# GD32C231 register map
File version: 1.0
CPU: CM23 r0p0, little endian, MPU, FPU, 4 interrupt priority bits
Registers are 32-bit, read-write, reset 0x0 unless marked. A register's access mark holds for its fields unless they carry their own. Offsets are from the block's base; [hi:lo] are bit positions.

## WWDGT — Window watchdog timer
Base 0x40002C00
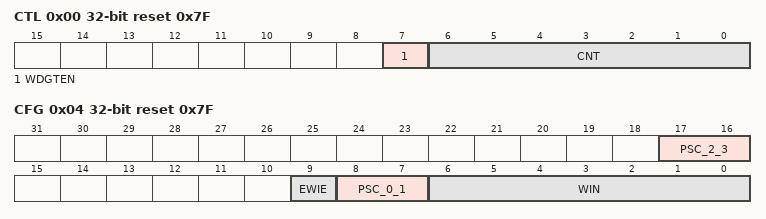
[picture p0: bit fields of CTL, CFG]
0x00 CTL reset 0x7F — Control register
  [7] WDGTEN — Activation bit
  [6:0] CNT — 7-bit counter
0x04 CFG reset 0x7F — Configuration register
  [17:16] PSC_2_3 — Prescaler
  [9] EWIE — Early wakeup interrupt
  [8:7] PSC_0_1 — Prescaler
  [6:0] WIN — 7-bit window value
0x08 STAT — Status register
  [0] EWIF — Early wakeup interrupt flag

## CMP — Comparator
Base 0x40017C00
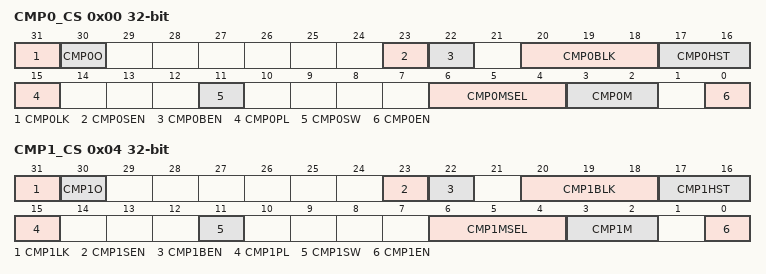
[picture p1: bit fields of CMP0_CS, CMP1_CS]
0x00 CMP0_CS access per field — CMP0 Control / Status register
  [31] CMP0LK rw — CMP0 lock
  [30] CMP0O ro — CMP0 output state
  [23] CMP0SEN rw — Voltage scaler enable bit
  [22] CMP0BEN rw — Scaler bridge enable bit
  [20:18] CMP0BLK rw — CMP0 output blanking source
  [17:16] CMP0HST rw — CMP0 hysteresis
  [15] CMP0PL rw — Polarity of CMP0 output
  [11] CMP0SW rw — CMP0 switch
  [6:4] CMP0MSEL rw — CMP0_IM input selection
  [3:2] CMP0M rw — CMP0 mode
  [0] CMP0EN rw — CMP0 enable
0x04 CMP1_CS access per field — CMP1 Control / Status register
  [31] CMP1LK rw — CMP1 lock
  [30] CMP1O ro — CMP1 output state
  [23] CMP1SEN rw — Voltage scaler enable bit
  [22] CMP1BEN rw — Scaler bridge enable bit
  [20:18] CMP1BLK rw — CMP1 output blanking source
  [17:16] CMP1HST rw — CMP1 hysteresis
  [15] CMP1PL rw — Polarity of CMP1 output
  [11] CMP1SW rw — CMP1 switch
  [6:4] CMP1MSEL rw — CMP1_IM input selection
  [3:2] CMP1M rw — CMP1 mode
  [0] CMP1EN rw — CMP1 enable.

## SPI1 — Serial peripheral interface
Base 0x40003800
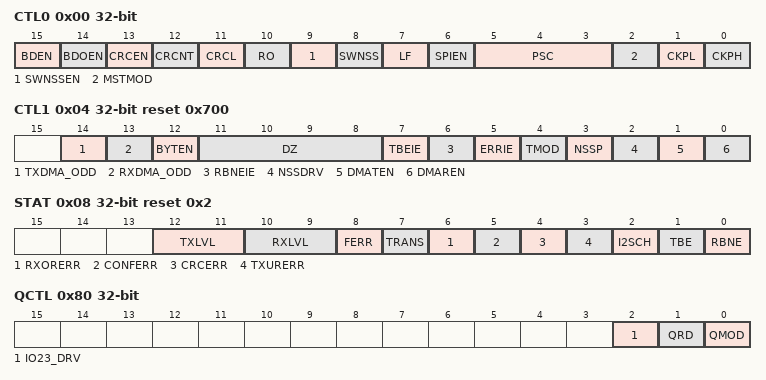
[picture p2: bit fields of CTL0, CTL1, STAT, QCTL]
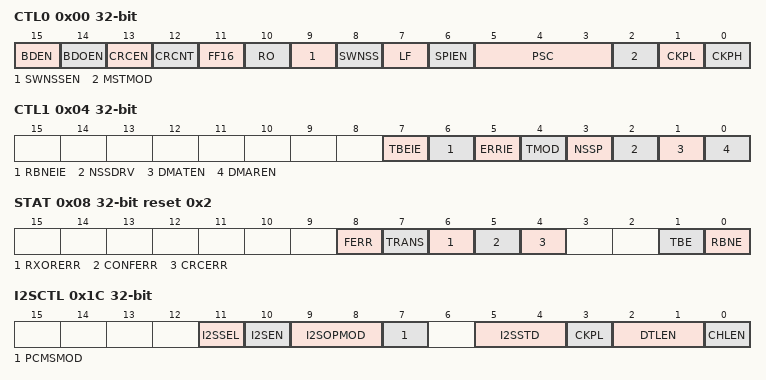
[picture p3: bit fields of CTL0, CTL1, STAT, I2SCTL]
0x00 CTL0 — control register 0
  [15] BDEN — Bidirectional enable
  [14] BDOEN — Bidirectional Transmit output enable
  [13] CRCEN — Hardware CRC calculation enable
  [12] CRCNT — CRC transfer next
  [11] CRCL — CRC length
  [10] RO — Receive only
  [9] SWNSSEN — NSS Software Mode Selection
  [8] SWNSS — NSS Pin Selection In NSS Software Mode
  [7] LF — LSB First Mode
  [6] SPIEN — SPI enable
  [5:3] PSC — Master Clock Prescaler Selection
  [2] MSTMOD — Master Mode Enable
  [1] CKPL — Clock Polarity Selection
  [0] CKPH — Clock Phase Selection
0x04 CTL1 reset 0x700 — control register 1
  [14] TXDMA_ODD — Odd bytes in TX DMA channel
  [13] RXDMA_ODD — Odd bytes in RX DMA channel
  [12] BYTEN — Byte access enable
  [11:8] DZ — Date size
  [7] TBEIE — Transmit Buffer Empty Interrupt Enable
  [6] RBNEIE — Receive Buffer Not Empty Interrupt Enable
  [5] ERRIE — Error interrupt enable
  [4] TMOD — SPI TI Mode Enable
  [3] NSSP — SPI NSS Pulse Mode Enable
  [2] NSSDRV — NSS output enable
  [1] DMATEN — Tx buffer DMA enable
  [0] DMAREN — Rx buffer DMA enable
0x08 STAT access per field reset 0x2 — status register
  [12:11] TXLVL ro — Tx FIFO level
  [10:9] RXLVL ro — Rx FIFO level
  [8] FERR rw — Format Error
  [7] TRANS ro — Transmitting ongoing Bit
  [6] RXORERR ro — Reception Overrun Error Bit
  [5] CONFERR ro — SPI Configuration error
  [4] CRCERR rw — SPI CRC Error Bit
  [3] TXURERR ro — Transmission underrun error bit
  [2] I2SCH ro — I2S channel side
  [1] TBE ro — Transmit Buffer Empty
  [0] RBNE ro — Receive Buffer Not Empty
0x0C DATA
  [15:0] DATA
0x10 CPCPOLY reset 0x7 — CRC polynomial register
  [15:0] CRCPOLY
0x14 RCRC ro — RX CRC register
  [15:0] RCRC — RX RCR register
0x18 TCRC ro — TX CRC register
  [15:0] TCRC — Tx CRC register
0x80 QCTL — SPI quad wird control register
  [2] IO23_DRV — Drive IO2 and IO3 enable
  [1] QRD — Quad wire read select
  [0] QMOD — Quad wire mode enable

## SPI0 — Serial Peripheral Interface 0
Base 0x40013000
0x00 CTL0 — control register 0
  [15] BDEN — Bidirectional enable
  [14] BDOEN — Bidirectional Transmit output enable
  [13] CRCEN — Hardware CRC calculation enable
  [12] CRCNT — CRC transfer next
  [11] FF16 — Data frame format
  [10] RO — Receive only
  [9] SWNSSEN — NSS Software Mode Selection
  [8] SWNSS — NSS Pin Selection In NSS Software Mode
  [7] LF — LSB First Mode
  [6] SPIEN — SPI enable
  [5:3] PSC — Master Clock Prescaler Selection
  [2] MSTMOD — Master Mode Enable
  [1] CKPL — Clock Polarity Selection
  [0] CKPH — Clock Phase Selection
0x04 CTL1 — control register 1
  [7] TBEIE — Transmit Buffer Empty Interrupt Enable
  [6] RBNEIE — Receive Buffer Not Empty Interrupt Enable
  [5] ERRIE — Error interrupt enable
  [4] TMOD — SPI TI Mode Enable
  [3] NSSP — SPI NSS Pulse Mode Enable
  [2] NSSDRV — NSS output enable
  [1] DMATEN — Tx buffer DMA enable
  [0] DMAREN — Rx buffer DMA enable
0x08 STAT access per field reset 0x2 — status register
  [8] FERR rw — Format Error
  [7] TRANS ro — Transmitting On-going Bit
  [6] RXORERR ro — Reception Overrun Error Bit
  [5] CONFERR ro — SPI Configuration error
  [4] CRCERR rw — SPI CRC Error Bit
  [1] TBE ro — Transmit Buffer Empty
  [0] RBNE ro — Receive Buffer Not Empty
0x0C DATA
  [15:0] DATA
0x10 CPCPOLY reset 0x7 — CRC polynomial register
  [15:0] CRCPOLY
0x14 RCRC ro — RX CRC register
  [15:0] RCRC — RX RCR register
0x18 TCRC ro — TX CRC register
  [15:0] TCRC — Tx CRC register
0x1C I2SCTL — I2S configuration register
  [11] I2SSEL — I2S mode selection
  [10] I2SEN — I2S Enable
  [9:8] I2SOPMOD — I2S configuration mode
  [7] PCMSMOD — PCM frame synchronization
  [5:4] I2SSTD — I2S standard selection
  [3] CKPL — Idle state clock polarity
  [2:1] DTLEN — Data length to be transferred
  [0] CHLEN — Channel length (number of bits per audio channel)
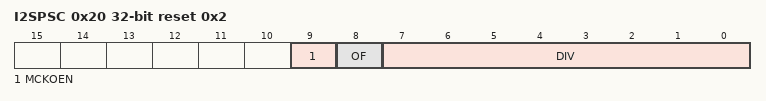
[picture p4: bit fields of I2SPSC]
0x20 I2SPSC reset 0x2 — I2S prescaler register
  [9] MCKOEN — I2S_MCK output enable
  [8] OF — Odd factor for the prescaler
  [7:0] DIV — Dividing factor for the prescaler
